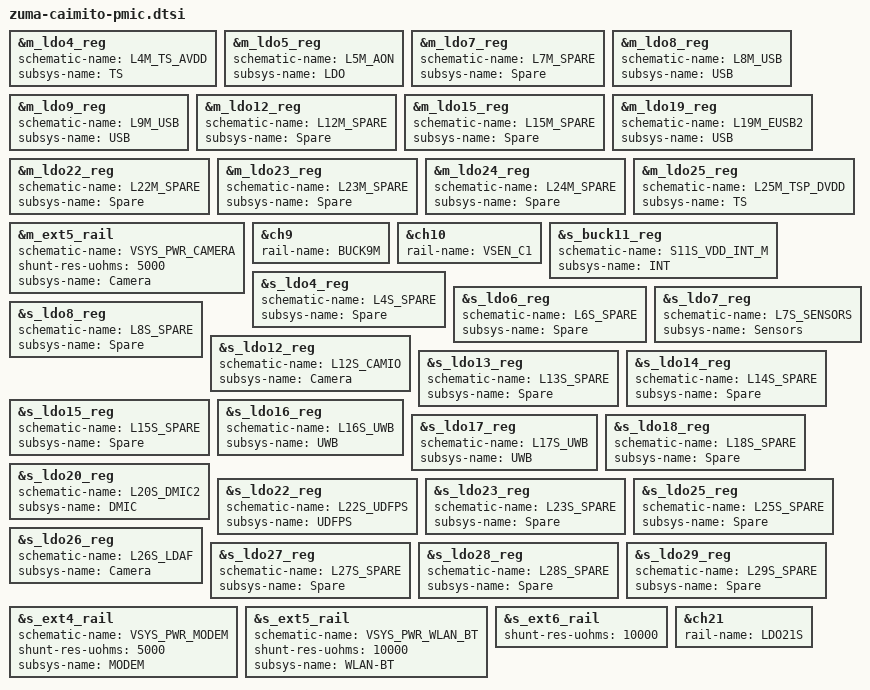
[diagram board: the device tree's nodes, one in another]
// SPDX-License-Identifier: GPL-2.0-only
/*
 *  PMIC settings
 *
 * Copyright 2023 Google LLC.
 *
 */

&m_ldo4_reg {
	schematic-name = "L4M_TS_AVDD";
	subsys-name = "TS";
};

&m_ldo5_reg {
	schematic-name = "L5M_AON";
	subsys-name = "LDO";
};

&m_ldo7_reg {
	schematic-name = "L7M_SPARE";
	subsys-name = "Spare";
};

&m_ldo8_reg {
	schematic-name = "L8M_USB";
	subsys-name = "USB";
};

&m_ldo9_reg {
	schematic-name = "L9M_USB";
	subsys-name = "USB";
};

&m_ldo12_reg {
	schematic-name = "L12M_SPARE";
	subsys-name = "Spare";
};

&m_ldo15_reg {
	schematic-name = "L15M_SPARE";
	subsys-name = "Spare";
};

&m_ldo19_reg {
	schematic-name = "L19M_EUSB2";
	subsys-name = "USB";
};

&m_ldo22_reg {
	schematic-name = "L22M_SPARE";
	subsys-name = "Spare";
};

&m_ldo23_reg {
	schematic-name = "L23M_SPARE";
	subsys-name = "Spare";
};

&m_ldo24_reg {
	schematic-name = "L24M_SPARE";
	subsys-name = "Spare";
};

&m_ldo25_reg {
	schematic-name = "L25M_TSP_DVDD";
	subsys-name = "TS";
};

&m_ext5_rail {
	schematic-name = "VSYS_PWR_CAMERA";
	shunt-res-uohms = <5000>;
	subsys-name = "Camera";
};

// Reselect rail from L15M_SPARE to S9M_VDD_CPUCL0_M on ch9
&ch9 {
	rail-name = "BUCK9M";
};

// Reselect rail from S9M_VDD_CPUCL0_M to VSYS_PWR_CAMERA
&ch10 {
	rail-name = "VSEN_C1";
};

&s_buck11_reg {
	schematic-name = "S11S_VDD_INT_M";
	subsys-name = "INT";
};

&s_ldo4_reg {
	schematic-name = "L4S_SPARE";
	subsys-name = "Spare";
};

&s_ldo6_reg {
	schematic-name = "L6S_SPARE";
	subsys-name = "Spare";
};

&s_ldo7_reg {
	schematic-name = "L7S_SENSORS";
	subsys-name = "Sensors";
};

&s_ldo8_reg {
	schematic-name = "L8S_SPARE";
	subsys-name = "Spare";
};

&s_ldo12_reg {
	schematic-name = "L12S_CAMIO";
	subsys-name = "Camera";
};

// MMC card is unused for P24
&s_ldo13_reg {
	schematic-name = "L13S_SPARE";
	subsys-name = "Spare";
};

&s_ldo14_reg {
	schematic-name = "L14S_SPARE";
	subsys-name = "Spare";
};

&s_ldo15_reg {
	schematic-name = "L15S_SPARE";
	subsys-name = "Spare";
};

&s_ldo16_reg {
	schematic-name = "L16S_UWB";
	subsys-name = "UWB";
};

&s_ldo17_reg {
	schematic-name = "L17S_UWB";
	subsys-name = "UWB";
};

&s_ldo18_reg {
	schematic-name = "L18S_SPARE";
	subsys-name = "Spare";
};

&s_ldo20_reg {
	schematic-name = "L20S_DMIC2";
	subsys-name = "DMIC";
};

&s_ldo22_reg {
	schematic-name = "L22S_UDFPS";
	subsys-name = "UDFPS";
};

&s_ldo23_reg {
	schematic-name = "L23S_SPARE";
	subsys-name = "Spare";
};

&s_ldo25_reg {
	schematic-name = "L25S_SPARE";
	subsys-name = "Spare";
};

&s_ldo26_reg {
	schematic-name = "L26S_LDAF";
	subsys-name = "Camera";
};

&s_ldo27_reg {
	schematic-name = "L27S_SPARE";
	subsys-name = "Spare";
};

&s_ldo28_reg {
	schematic-name = "L28S_SPARE";
	subsys-name = "Spare";
};

&s_ldo29_reg {
	schematic-name = "L29S_SPARE";
	subsys-name = "Spare";
};

&s_ext4_rail {
	schematic-name = "VSYS_PWR_MODEM";
	shunt-res-uohms = <5000>;
	subsys-name = "MODEM";
};

&s_ext5_rail {
	schematic-name = "VSYS_PWR_WLAN_BT";
	shunt-res-uohms = <10000>;
	subsys-name = "WLAN-BT";
};

&s_ext6_rail {
	shunt-res-uohms = <10000>;
};

// Reselect rail from L29S_SPARE to L21S_VDD2L_MEM on ch21
&ch21 {
	rail-name = "LDO21S";
};
